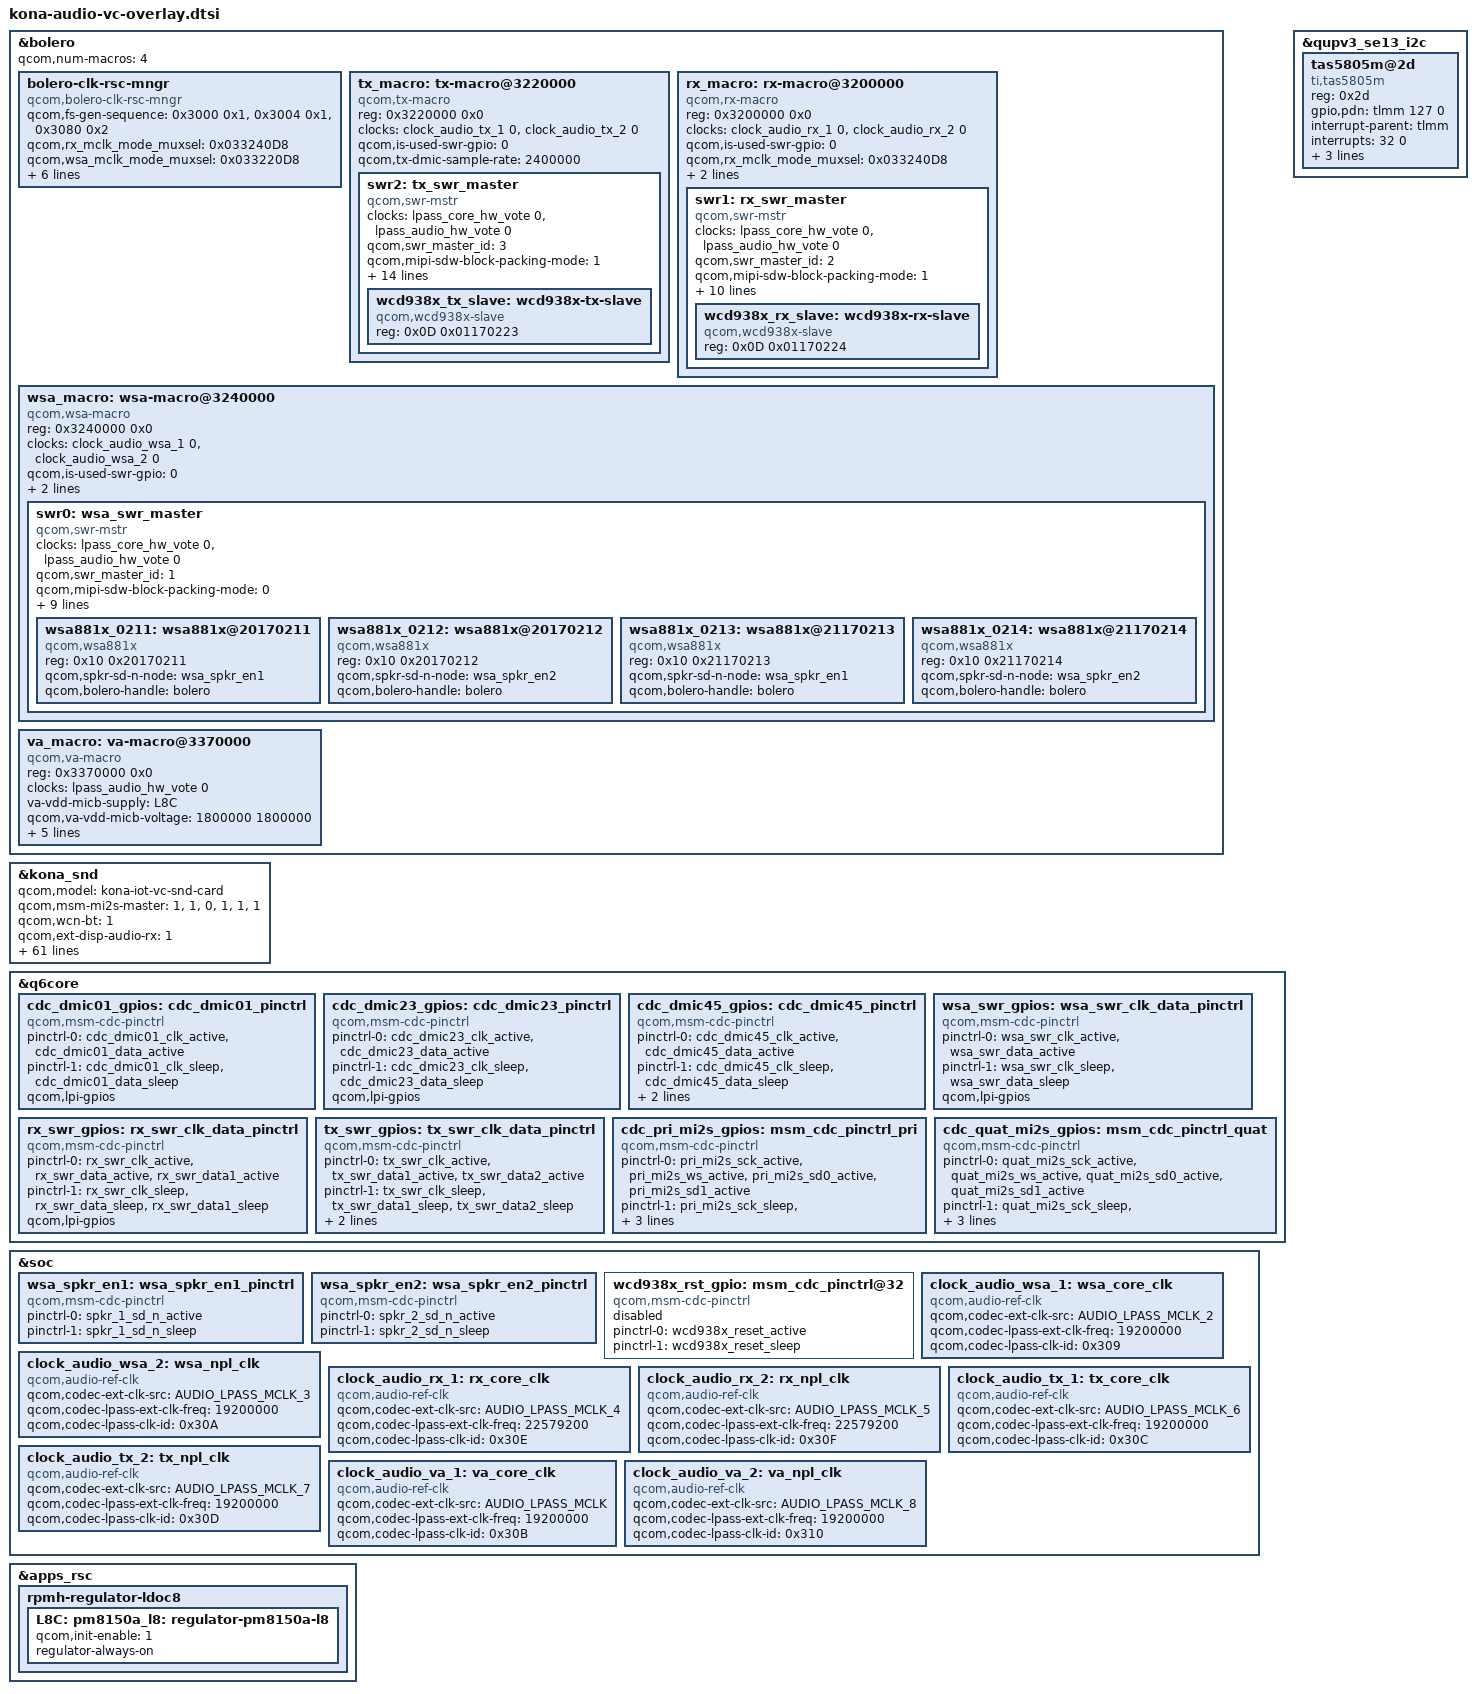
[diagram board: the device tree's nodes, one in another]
#include <dt-bindings/clock/qcom,audio-ext-clk.h>
#include <dt-bindings/sound/qcom,bolero-clk-rsc.h>
#include <dt-bindings/sound/audio-codec-port-types.h>
#include <dt-bindings/interrupt-controller/arm-gic.h>
#include "kona-lpi.dtsi"
/*#include "kona-va-bolero.dtsi"*/

&bolero {
	qcom,num-macros = <4>;
	bolero-clk-rsc-mngr {
		compatible = "qcom,bolero-clk-rsc-mngr";
		qcom,fs-gen-sequence = <0x3000 0x1>,
					<0x3004 0x1>, <0x3080 0x2>;
	qcom,rx_mclk_mode_muxsel = <0x033240D8>;
	qcom,wsa_mclk_mode_muxsel = <0x033220D8>;
	qcom,va_mclk_mode_muxsel = <0x033A0000>;
	clock-names = "tx_core_clk", "tx_npl_clk", "rx_core_clk", "rx_npl_clk",
		 "wsa_core_clk", "wsa_npl_clk", "va_core_clk", "va_npl_clk";
	clocks = <&clock_audio_tx_1 0>, <&clock_audio_tx_2 0>,
		<&clock_audio_rx_1 0>, <&clock_audio_rx_2 0>,
		<&clock_audio_wsa_1 0>, <&clock_audio_wsa_2 0>,
		<&clock_audio_va_1 0>, <&clock_audio_va_2 0>;
	};

	tx_macro: tx-macro@3220000 {
		compatible = "qcom,tx-macro";
		reg = <0x3220000 0x0>;
		clock-names = "tx_core_clk", "tx_npl_clk";
		clocks = <&clock_audio_tx_1 0>,
			 <&clock_audio_tx_2 0>;
		qcom,is-used-swr-gpio = <0>;
		qcom,tx-dmic-sample-rate = <2400000>;
		swr2: tx_swr_master {
				compatible = "qcom,swr-mstr";
				#address-cells = <2>;
				#size-cells = <0>;
				clock-names = "lpass_core_hw_vote",
								"lpass_audio_hw_vote";
				clocks = <&lpass_core_hw_vote 0>,
								<&lpass_audio_hw_vote 0>;
				qcom,swr_master_id = <3>;
				qcom,mipi-sdw-block-packing-mode = <1>;
				swrm-io-base = <0x3230000 0x0>;
				interrupts-extended =  <&intc GIC_SPI 297 IRQ_TYPE_LEVEL_HIGH>,
											<&pdc 109 IRQ_TYPE_LEVEL_HIGH>;
				interrupt-names = "swr_master_irq", "swr_wake_irq";
				qcom,swr-wakeup-required = <1>;
				qcom,swr-num-ports = <5>;
				qcom,swr-port-mapping = <1 PCM_OUT1 0xF>,
							<2 ADC1 0x1>, <2 ADC2 0x2>,
							<3 ADC3 0x1>, <3 ADC4 0x2>,
							<4 DMIC0 0x1>, <4 DMIC1 0x2>,
							<4 DMIC2 0x4>, <4 DMIC3 0x8>,
							<5 DMIC4 0x1>, <5 DMIC5 0x2>,
							<5 DMIC6 0x4>, <5 DMIC7 0x8>;
				qcom,swr-num-dev = <1>;
				qcom,swr-clock-stop-mode0 = <1>;
				qcom,swr-mstr-irq-wakeup-capable = <1>;
				wcd938x_tx_slave: wcd938x-tx-slave {
							compatible = "qcom,wcd938x-slave";
							reg = <0x0D 0x01170223>;
			};
		};
	};

	rx_macro: rx-macro@3200000 {
		compatible = "qcom,rx-macro";
		reg = <0x3200000 0x0>;
		clock-names = "rx_core_clk", "rx_npl_clk";
		clocks = <&clock_audio_rx_1 0>,
			 <&clock_audio_rx_2 0>;
		qcom,is-used-swr-gpio = <0>;
		qcom,rx_mclk_mode_muxsel = <0x033240D8>;
		qcom,rx-bcl-pmic-params = /bits/ 8 <0x00 0x04 0x3E>;
		qcom,default-clk-id = <TX_CORE_CLK>;
		swr1: rx_swr_master {
				compatible = "qcom,swr-mstr";
				#address-cells = <2>;
				#size-cells = <0>;
				clock-names = "lpass_core_hw_vote",
									"lpass_audio_hw_vote";
				clocks = <&lpass_core_hw_vote 0>,
								<&lpass_audio_hw_vote 0>;
				qcom,swr_master_id = <2>;
				qcom,mipi-sdw-block-packing-mode = <1>;
				swrm-io-base = <0x3210000 0x0>;
				interrupts = <GIC_SPI 298 IRQ_TYPE_LEVEL_HIGH>;
				interrupt-names = "swr_master_irq";
				qcom,swr-num-ports = <5>;
				qcom,disable-div2-clk-switch = <1>;
				qcom,swr-port-mapping = <1 HPH_L 0x1>,
							<1 HPH_R 0x2>, <2 CLSH 0x1>,
							<3 COMP_L 0x1>, <3 COMP_R 0x2>,
							<4 LO 0x1>, <5 DSD_L 0x1>,
							<5 DSD_R 0x2>;
				qcom,swr-num-dev = <1>;
				qcom,swr-clock-stop-mode0 = <1>;
				wcd938x_rx_slave: wcd938x-rx-slave {
						compatible = "qcom,wcd938x-slave";
						reg = <0x0D 0x01170224>;
				};
		};
	};

	wsa_macro: wsa-macro@3240000 {
		compatible = "qcom,wsa-macro";
		reg = <0x3240000 0x0>;
		clock-names = "wsa_core_clk", "wsa_npl_clk";
		clocks = <&clock_audio_wsa_1 0>,
			 <&clock_audio_wsa_2 0>;
		qcom,is-used-swr-gpio = <0>;
		qcom,wsa-bcl-pmic-params = /bits/ 8 <0x00 0x04 0x3E>;
		qcom,default-clk-id = <TX_CORE_CLK>;
		swr0: wsa_swr_master {
				compatible = "qcom,swr-mstr";
				#address-cells = <2>;
				#size-cells = <0>;
				clock-names = "lpass_core_hw_vote",
									"lpass_audio_hw_vote";
				clocks = <&lpass_core_hw_vote 0>,
								<&lpass_audio_hw_vote 0>;
				qcom,swr_master_id = <1>;
				qcom,mipi-sdw-block-packing-mode = <0>;
				swrm-io-base = <0x3250000 0x0>;
				interrupts = <GIC_SPI 202 IRQ_TYPE_LEVEL_HIGH>;
				interrupt-names = "swr_master_irq";
				qcom,swr-num-ports = <8>;
				qcom,swr-port-mapping = <1 SPKR_L 0x1>,
							<2 SPKR_L_COMP 0xF>, <3 SPKR_L_BOOST 0x3>,
							<4 SPKR_R 0x1>, <5 SPKR_R_COMP 0xF>,
							<6 SPKR_R_BOOST 0x3>, <7 SPKR_L_VI 0x3>,
							<8 SPKR_R_VI 0x3>;
				qcom,swr-num-dev = <2>;

				wsa881x_0211: wsa881x@20170211 {
						compatible = "qcom,wsa881x";
						reg = <0x10 0x20170211>;
						qcom,spkr-sd-n-node = <&wsa_spkr_en1>;
						qcom,bolero-handle = <&bolero>;
				};

				wsa881x_0212: wsa881x@20170212 {
						compatible = "qcom,wsa881x";
						reg = <0x10 0x20170212>;
						qcom,spkr-sd-n-node = <&wsa_spkr_en2>;
						qcom,bolero-handle = <&bolero>;
				};

				wsa881x_0213: wsa881x@21170213 {
						compatible = "qcom,wsa881x";
						reg = <0x10 0x21170213>;
						qcom,spkr-sd-n-node = <&wsa_spkr_en1>;
						qcom,bolero-handle = <&bolero>;
				};

				wsa881x_0214: wsa881x@21170214 {
						compatible = "qcom,wsa881x";
						reg = <0x10 0x21170214>;
						qcom,spkr-sd-n-node = <&wsa_spkr_en2>;
						qcom,bolero-handle = <&bolero>;
				};
		};
	};

	va_macro: va-macro@3370000 {
		compatible = "qcom,va-macro";
		reg = <0x3370000 0x0>;
		clock-names = "lpass_audio_hw_vote";
		clocks = <&lpass_audio_hw_vote 0>;
		va-vdd-micb-supply = <&L8C>;
		qcom,va-vdd-micb-voltage = <1800000 1800000>;
		qcom,va-vdd-micb-current = <11200>;
		qcom,va-dmic-sample-rate = <3200000>;
		qcom,va-clk-mux-select = <1>;
		qcom,va-island-mode-muxsel = <0x033A0000>;
		qcom,default-clk-id = <TX_CORE_CLK>;
	};
};

&kona_snd {
	qcom,model = "kona-iot-vc-snd-card";
	qcom,msm-mi2s-master = <1>, <1>, <0>, <1>, <1>, <1>;
	qcom,wcn-bt = <1>;
	qcom,ext-disp-audio-rx = <1>;
	qcom,tdm-max-slots = <8>;
	qcom,afe-rxtx-lb = <1>;
	qcom,audio-routing =
		"TX DMIC0", "Digital Mic0",
		"TX DMIC1", "Digital Mic1",
		"TX DMIC2", "Digital Mic2",
		"TX DMIC3", "Digital Mic3",
		"TX DMIC4", "Digital Mic4",
		"TX DMIC5", "Digital Mic5",
		"IN1_HPHL", "HPHL_OUT",
		"IN2_HPHR", "HPHR_OUT",
		"IN3_AUX", "AUX_OUT",
		"TX SWR_ADC0", "ADC1_OUTPUT",
		"TX SWR_ADC1", "ADC2_OUTPUT",
		"TX SWR_ADC2", "ADC3_OUTPUT",
		"TX SWR_ADC3", "ADC4_OUTPUT",
		"TX SWR_DMIC0", "DMIC1_OUTPUT",
		"TX SWR_DMIC1", "DMIC2_OUTPUT",
		"TX SWR_DMIC2", "DMIC3_OUTPUT",
		"TX SWR_DMIC3", "DMIC4_OUTPUT",
		"TX SWR_DMIC4", "DMIC5_OUTPUT",
		"TX SWR_DMIC5", "DMIC6_OUTPUT",
		"TX SWR_DMIC6", "DMIC7_OUTPUT",
		"TX SWR_DMIC7", "DMIC8_OUTPUT",
		"WSA SRC0_INP", "SRC0",
		"WSA_TX DEC0_INP", "TX DEC0 MUX",
		"WSA_TX DEC1_INP", "TX DEC1 MUX",
		"RX_TX DEC0_INP", "TX DEC0 MUX",
		"RX_TX DEC1_INP", "TX DEC1 MUX",
		"RX_TX DEC2_INP", "TX DEC2 MUX",
		"RX_TX DEC3_INP", "TX DEC3 MUX",
		"SpkrLeft IN", "WSA_SPK1 OUT",
		"SpkrRight IN", "WSA_SPK2 OUT",
		"VA_AIF1 CAP", "VA_SWR_CLK",
		"VA_AIF2 CAP", "VA_SWR_CLK",
		"VA_AIF3 CAP", "VA_SWR_CLK",
		"VA DMIC0", "Digital Mic0",
		"VA DMIC1", "Digital Mic1",
		"VA DMIC2", "Digital Mic2",
		"VA DMIC3", "Digital Mic3",
		"VA DMIC4", "Digital Mic4",
		"VA DMIC5", "Digital Mic5",
		"VA SWR_ADC0", "VA_SWR_CLK",
		"VA SWR_ADC1", "VA_SWR_CLK",
		"VA SWR_ADC2", "VA_SWR_CLK",
		"VA SWR_ADC3", "VA_SWR_CLK",
		"VA SWR_MIC0", "VA_SWR_CLK",
		"VA SWR_MIC1", "VA_SWR_CLK",
		"VA SWR_MIC2", "VA_SWR_CLK",
		"VA SWR_MIC3", "VA_SWR_CLK",
		"VA SWR_MIC4", "VA_SWR_CLK",
		"VA SWR_MIC5", "VA_SWR_CLK",
		"VA SWR_MIC6", "VA_SWR_CLK",
		"VA SWR_MIC7", "VA_SWR_CLK",
		"VA SWR_ADC0", "ADC1_OUTPUT",
		"VA SWR_ADC1", "ADC2_OUTPUT",
		"VA SWR_ADC2", "ADC3_OUTPUT",
		"VA SWR_ADC3", "ADC4_OUTPUT",
		"VA SWR_MIC0", "DMIC1_OUTPUT",
		"VA SWR_MIC1", "DMIC2_OUTPUT",
		"VA SWR_MIC2", "DMIC3_OUTPUT",
		"VA SWR_MIC3", "DMIC4_OUTPUT",
		"VA SWR_MIC4", "DMIC5_OUTPUT",
		"VA SWR_MIC5", "DMIC6_OUTPUT",
		"VA SWR_MIC6", "DMIC7_OUTPUT",
		"VA SWR_MIC7", "DMIC8_OUTPUT";
	qcom,msm-mbhc-hphl-swh = <1>;
	qcom,msm-mbhc-gnd-swh = <1>;
	qcom,cdc-dmic01-gpios = <&cdc_dmic01_gpios>;
	qcom,cdc-dmic23-gpios = <&cdc_dmic23_gpios>;
	qcom,cdc-dmic45-gpios = <&cdc_dmic45_gpios>;
	asoc-codec  = <&stub_codec>, <&bolero>, <&ext_disp_audio_codec>;
	asoc-codec-names = "msm-stub-codec.1", "bolero_codec",
			   "msm-ext-disp-audio-codec-rx";
	qcom,wsa-max-devs = <0>;
	qcom,codec-max-aux-devs = <0>;
	qcom,msm_audio_ssr_devs = <&audio_apr>, <&q6core>, <&lpi_tlmm>,
				  <&bolero>;
	qcom,pri-mi2s-gpios = <&cdc_pri_mi2s_gpios>;
	qcom,quat-mi2s-gpios = <&cdc_quat_mi2s_gpios>;
	qcom,tert-mi2s-gpios = <&cdc_tert_mi2s_gpios>;
	qcom,wsa-bolero-codec = <0>;
};

&q6core {
	cdc_dmic01_gpios: cdc_dmic01_pinctrl {
		compatible = "qcom,msm-cdc-pinctrl";
		pinctrl-names = "aud_active", "aud_sleep";
		pinctrl-0 = <&cdc_dmic01_clk_active &cdc_dmic01_data_active>;
		pinctrl-1 = <&cdc_dmic01_clk_sleep &cdc_dmic01_data_sleep>;
		qcom,lpi-gpios;
	};

	cdc_dmic23_gpios: cdc_dmic23_pinctrl {
		compatible = "qcom,msm-cdc-pinctrl";
		pinctrl-names = "aud_active", "aud_sleep";
		pinctrl-0 = <&cdc_dmic23_clk_active &cdc_dmic23_data_active>;
		pinctrl-1 = <&cdc_dmic23_clk_sleep &cdc_dmic23_data_sleep>;
		qcom,lpi-gpios;
	};

	cdc_dmic45_gpios: cdc_dmic45_pinctrl {
		compatible = "qcom,msm-cdc-pinctrl";
		pinctrl-names = "aud_active", "aud_sleep";
		pinctrl-0 = <&cdc_dmic45_clk_active &cdc_dmic45_data_active>;
		pinctrl-1 = <&cdc_dmic45_clk_sleep &cdc_dmic45_data_sleep>;
		qcom,lpi-gpios;
		qcom,tlmm-gpio = <158>;
	};

	wsa_swr_gpios: wsa_swr_clk_data_pinctrl {
		compatible = "qcom,msm-cdc-pinctrl";
		pinctrl-names = "aud_active", "aud_sleep";
		pinctrl-0 = <&wsa_swr_clk_active &wsa_swr_data_active>;
		pinctrl-1 = <&wsa_swr_clk_sleep &wsa_swr_data_sleep>;
		qcom,lpi-gpios;
	};

	rx_swr_gpios: rx_swr_clk_data_pinctrl {
		compatible = "qcom,msm-cdc-pinctrl";
		pinctrl-names = "aud_active", "aud_sleep";
		pinctrl-0 = <&rx_swr_clk_active &rx_swr_data_active
				&rx_swr_data1_active>;
		pinctrl-1 = <&rx_swr_clk_sleep &rx_swr_data_sleep
				&rx_swr_data1_sleep>;
		qcom,lpi-gpios;
	};

	tx_swr_gpios: tx_swr_clk_data_pinctrl {
		compatible = "qcom,msm-cdc-pinctrl";
		pinctrl-names = "aud_active", "aud_sleep";
		pinctrl-0 = <&tx_swr_clk_active &tx_swr_data1_active
			    &tx_swr_data2_active>;
		pinctrl-1 = <&tx_swr_clk_sleep &tx_swr_data1_sleep
			    &tx_swr_data2_sleep>;
		qcom,lpi-gpios;
		qcom,tlmm-gpio = <147>;
	};

	cdc_pri_mi2s_gpios: msm_cdc_pinctrl_pri {
		compatible = "qcom,msm-cdc-pinctrl";
		pinctrl-names = "aud_active", "aud_sleep";
		pinctrl-0 = <&pri_mi2s_sck_active &pri_mi2s_ws_active
				&pri_mi2s_sd0_active &pri_mi2s_sd1_active>;
		pinctrl-1 = <&pri_mi2s_sck_sleep &pri_mi2s_ws_sleep
				&pri_mi2s_sd0_sleep &pri_mi2s_sd1_sleep>;
		qcom,lpi-gpios;
	};

	cdc_quat_mi2s_gpios: msm_cdc_pinctrl_quat {
		compatible = "qcom,msm-cdc-pinctrl";
		pinctrl-names = "aud_active", "aud_sleep";
		pinctrl-0 = <&quat_mi2s_sck_active &quat_mi2s_ws_active
				&quat_mi2s_sd0_active &quat_mi2s_sd1_active>;
		pinctrl-1 = <&quat_mi2s_sck_sleep &quat_mi2s_ws_sleep
				&quat_mi2s_sd0_sleep &quat_mi2s_sd1_sleep>;
		qcom,lpi-gpios;
	};
};

&soc {
	wsa_spkr_en1: wsa_spkr_en1_pinctrl {
		compatible = "qcom,msm-cdc-pinctrl";
		pinctrl-names = "aud_active", "aud_sleep";
		pinctrl-0 = <&spkr_1_sd_n_active>;
		pinctrl-1 = <&spkr_1_sd_n_sleep>;
	};

	wsa_spkr_en2: wsa_spkr_en2_pinctrl {
		compatible = "qcom,msm-cdc-pinctrl";
		pinctrl-names = "aud_active", "aud_sleep";
		pinctrl-0 = <&spkr_2_sd_n_active>;
		pinctrl-1 = <&spkr_2_sd_n_sleep>;
	};

	wcd938x_rst_gpio: msm_cdc_pinctrl@32 {
		status = "disabled";
		compatible = "qcom,msm-cdc-pinctrl";
		pinctrl-names = "aud_active", "aud_sleep";
		pinctrl-0 = <&wcd938x_reset_active>;
		pinctrl-1 = <&wcd938x_reset_sleep>;
	};

	clock_audio_wsa_1: wsa_core_clk {
		compatible = "qcom,audio-ref-clk";
		qcom,codec-ext-clk-src = <AUDIO_LPASS_MCLK_2>;
		qcom,codec-lpass-ext-clk-freq = <19200000>;
		qcom,codec-lpass-clk-id = <0x309>;
		#clock-cells = <1>;
	};

	clock_audio_wsa_2: wsa_npl_clk {
		compatible = "qcom,audio-ref-clk";
		qcom,codec-ext-clk-src = <AUDIO_LPASS_MCLK_3>;
		qcom,codec-lpass-ext-clk-freq = <19200000>;
		qcom,codec-lpass-clk-id = <0x30A>;
		#clock-cells = <1>;
	};

	clock_audio_rx_1: rx_core_clk {
		compatible = "qcom,audio-ref-clk";
		qcom,codec-ext-clk-src = <AUDIO_LPASS_MCLK_4>;
		qcom,codec-lpass-ext-clk-freq = <22579200>;
		qcom,codec-lpass-clk-id = <0x30E>;
		#clock-cells = <1>;
	};

	clock_audio_rx_2: rx_npl_clk {
		compatible = "qcom,audio-ref-clk";
		qcom,codec-ext-clk-src = <AUDIO_LPASS_MCLK_5>;
		qcom,codec-lpass-ext-clk-freq = <22579200>;
		qcom,codec-lpass-clk-id = <0x30F>;
		#clock-cells = <1>;
	};

	clock_audio_tx_1: tx_core_clk {
		compatible = "qcom,audio-ref-clk";
		qcom,codec-ext-clk-src = <AUDIO_LPASS_MCLK_6>;
		qcom,codec-lpass-ext-clk-freq = <19200000>;
		qcom,codec-lpass-clk-id = <0x30C>;
		#clock-cells = <1>;
	};

	clock_audio_tx_2: tx_npl_clk {
		compatible = "qcom,audio-ref-clk";
		qcom,codec-ext-clk-src = <AUDIO_LPASS_MCLK_7>;
		qcom,codec-lpass-ext-clk-freq = <19200000>;
		qcom,codec-lpass-clk-id = <0x30D>;
		#clock-cells = <1>;
	};

	clock_audio_va_1: va_core_clk {
		compatible = "qcom,audio-ref-clk";
		qcom,codec-ext-clk-src = <AUDIO_LPASS_MCLK>;
		qcom,codec-lpass-ext-clk-freq = <19200000>;
		qcom,codec-lpass-clk-id = <0x30B>;
		#clock-cells = <1>;
	};

	clock_audio_va_2: va_npl_clk {
		compatible = "qcom,audio-ref-clk";
		qcom,codec-ext-clk-src = <AUDIO_LPASS_MCLK_8>;
		qcom,codec-lpass-ext-clk-freq = <19200000>;
		qcom,codec-lpass-clk-id = <0x310>;
		#clock-cells = <1>;
	};
};

&apps_rsc {
	rpmh-regulator-ldoc8 {
		L8C: pm8150a_l8: regulator-pm8150a-l8 {
				 qcom,init-enable = <1>;
				 regulator-always-on;
		};
	};
};

&qupv3_se13_i2c {
	status = "ok";
	tas5805m@2d {
		compatible = "ti,tas5805m";
		reg = <0x2d>;
		gpio,pdn = <&tlmm 127 0>;

		interrupt-parent = <&tlmm>;
		interrupts = <32 0>;
		gpio,hpd = <&tlmm 32 0>;

		pinctrl-names = "default";
		pinctrl-0 = <&spkr_2_sd_n_sleep &line_out_hpd_default>;
	};
};
